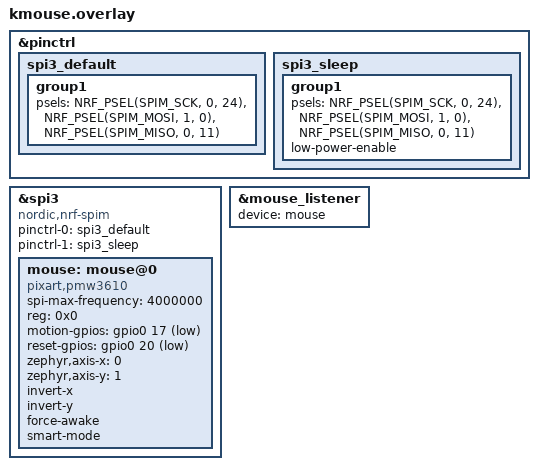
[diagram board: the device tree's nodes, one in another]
/*
* Copyright (c) 2020 Pete Johanson
*
* SPDX-License-Identifier: MIT
*/

#include "kmouse.dtsi"

&pinctrl {
    spi3_default: spi3_default {
        group1 {
            psels = <NRF_PSEL(SPIM_SCK, 0, 24)>,
                    <NRF_PSEL(SPIM_MOSI, 1, 0)>,
                    <NRF_PSEL(SPIM_MISO, 0, 11)>;
        };
    };

    spi3_sleep: spi3_sleep {
        group1 {
            psels = <NRF_PSEL(SPIM_SCK, 0, 24)>,
                    <NRF_PSEL(SPIM_MOSI, 1, 0)>,
                    <NRF_PSEL(SPIM_MISO, 0, 11)>;
                    low-power-enable;
        };
    };
};

&spi3 {
    compatible = "nordic,nrf-spim";
    status = "okay";

    pinctrl-0 = <&spi3_default>;
    pinctrl-1 = <&spi3_sleep>;
    pinctrl-names = "default", "sleep";

    mouse: mouse@0 {
        compatible = "pixart,pmw3610";
        spi-max-frequency = <4000000>;
        reg = <0x0>;
        /*cs-gpios = <&gpio0 22 GPIO_ACTIVE_LOW>;*/
        motion-gpios = <&gpio0 17 (GPIO_ACTIVE_LOW | GPIO_PULL_UP)>;
        reset-gpios = <&gpio0 20 (GPIO_ACTIVE_LOW | GPIO_PULL_UP)>;
        zephyr,axis-x = <0>;
        zephyr,axis-y = <1>;
        invert-x;
        invert-y;
        force-awake;
        smart-mode;
    };
};


&mouse_listener {
    device = <&mouse>;
};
